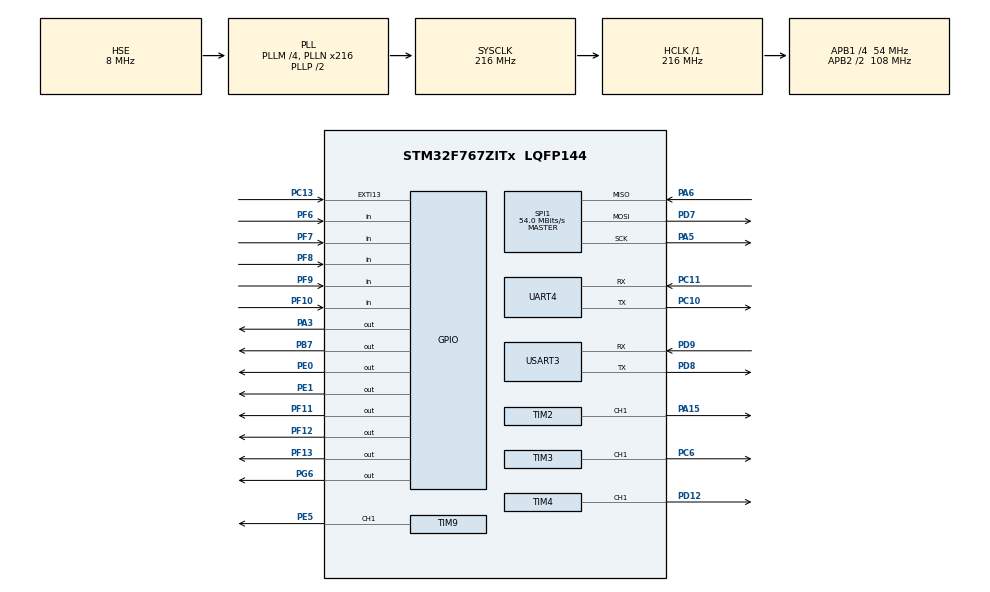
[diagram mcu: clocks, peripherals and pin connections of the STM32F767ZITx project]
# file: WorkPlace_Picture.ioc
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Mcu.Family=STM32F7
Mcu.Name=STM32F767ZITx
Mcu.Package=LQFP144
NVIC.PriorityGroup=NVIC_PRIORITYGROUP_2
NVIC.TIM2_IRQn=true\:0\:0\:false\:false\:true\:true\:true
NVIC.TIM3_IRQn=true\:0\:0\:false\:false\:true\:true\:true
NVIC.TIM4_IRQn=true\:0\:0\:false\:false\:true\:true\:true
NVIC.UART4_IRQn=true\:0\:0\:false\:false\:true\:true\:true
NVIC.USART3_IRQn=true\:0\:0\:false\:false\:true\:true\:true
PA0/WKUP.Mode=SYS_WakeUp0
PA0/WKUP.Signal=SYS_WKUP1
PA1.GPIO_Mode=GPIO_MODE_AF_PP
PA1.GPIO_PuPd=GPIO_NOPULL
PA1.GPIO_Speed=GPIO_SPEED_FREQ_VERY_HIGH
PA1.Signal=ETH_REF_CLK
PA10.GPIO_Mode=GPIO_MODE_AF_PP
PA10.GPIO_PuPd=GPIO_NOPULL
PA10.GPIO_Speed=GPIO_SPEED_FREQ_VERY_HIGH
PA10.Signal=USB_OTG_FS_ID
PA11.GPIO_Mode=GPIO_MODE_AF_PP
PA11.GPIO_PuPd=GPIO_NOPULL
PA11.GPIO_Speed=GPIO_SPEED_FREQ_VERY_HIGH
PA11.Signal=USB_OTG_FS_DM
PA12.GPIO_Mode=GPIO_MODE_AF_PP
PA12.GPIO_PuPd=GPIO_NOPULL
PA12.GPIO_Speed=GPIO_SPEED_FREQ_VERY_HIGH
PA12.Signal=USB_OTG_FS_DP
PA13.Mode=Serial_Wire
PA13.Signal=SYS_JTMS-SWDIO
PA14.Mode=Serial_Wire
PA14.Signal=SYS_JTCK-SWCLK
PA15.Signal=S_TIM2_CH1_ETR
PA2.GPIO_Mode=GPIO_MODE_AF_PP
PA2.GPIO_PuPd=GPIO_NOPULL
PA2.GPIO_Speed=GPIO_SPEED_FREQ_VERY_HIGH
PA2.Signal=ETH_MDIO
PA3.Signal=GPIO_Output
PA5.Mode=Full_Duplex_Master
PA5.Signal=SPI1_SCK
PA6.Mode=Full_Duplex_Master
PA6.Signal=SPI1_MISO
PA7.GPIO_Mode=GPIO_MODE_AF_PP
PA7.GPIO_PuPd=GPIO_NOPULL
PA7.GPIO_Speed=GPIO_SPEED_FREQ_VERY_HIGH
PA7.Signal=ETH_CRS_DV
PA8.GPIO_Mode=GPIO_MODE_AF_PP
PA8.GPIO_PuPd=GPIO_NOPULL
PA8.GPIO_Speed=GPIO_SPEED_FREQ_VERY_HIGH
PA8.Signal=USB_OTG_FS_SOF
PA9.GPIO_Mode=GPIO_MODE_INPUT
PA9.GPIO_PuPd=GPIO_NOPULL
PA9.Signal=USB_OTG_FS_VBUS
PB13.GPIO_Mode=GPIO_MODE_AF_PP
PB13.GPIO_PuPd=GPIO_NOPULL
PB13.GPIO_Speed=GPIO_SPEED_FREQ_VERY_HIGH
PB13.Signal=ETH_TXD1
PB3.Signal=SYS_JTDO-SWO
PB7.Signal=GPIO_Output
PC1.GPIO_Mode=GPIO_MODE_AF_PP
PC1.GPIO_PuPd=GPIO_NOPULL
PC1.GPIO_Speed=GPIO_SPEED_FREQ_VERY_HIGH
PC1.Signal=ETH_MDC
PC10.Mode=Asynchronous
PC10.Signal=UART4_TX
PC11.Mode=Asynchronous
PC11.Signal=UART4_RX
PC13.GPIO_ModeDefaultEXTI=GPIO_MODE_IT_RISING
PC13.GPIO_PuPd=GPIO_NOPULL
PC13.Signal=GPXTI13
PC14/OSC32_IN.Mode=LSE-External-Oscillator
PC14/OSC32_IN.Signal=RCC_OSC32_IN
PC15/OSC32_OUT.Mode=LSE-External-Oscillator
PC15/OSC32_OUT.Signal=RCC_OSC32_OUT
PC4.GPIO_Mode=GPIO_MODE_AF_PP
PC4.GPIO_PuPd=GPIO_NOPULL
PC4.GPIO_Speed=GPIO_SPEED_FREQ_VERY_HIGH
PC4.Signal=ETH_RXD0
PC5.GPIO_Mode=GPIO_MODE_AF_PP
PC5.GPIO_PuPd=GPIO_NOPULL
PC5.GPIO_Speed=GPIO_SPEED_FREQ_VERY_HIGH
PC5.Signal=ETH_RXD1
PC6.Signal=S_TIM3_CH1
PD12.Signal=S_TIM4_CH1
PD7.Mode=Full_Duplex_Master
PD7.Signal=SPI1_MOSI
PD8.GPIO_ModeDefaultPP=GPIO_MODE_AF_PP
PD8.GPIO_PuPd=GPIO_NOPULL
PD8.GPIO_Speed=GPIO_SPEED_FREQ_VERY_HIGH
PD8.Mode=Asynchronous
PD8.Signal=USART3_TX
PD9.GPIO_ModeDefaultPP=GPIO_MODE_AF_PP
PD9.GPIO_PuPd=GPIO_NOPULL
PD9.GPIO_Speed=GPIO_SPEED_FREQ_VERY_HIGH
PD9.Mode=Asynchronous
PD9.Signal=USART3_RX
PE0.Signal=GPIO_Output
PE1.Signal=GPIO_Output
PE5.Signal=S_TIM9_CH1
PF10.Signal=GPIO_Input
PF11.Signal=GPIO_Output
PF12.Signal=GPIO_Output
PF13.Signal=GPIO_Output
PF6.Signal=GPIO_Input
PF7.Signal=GPIO_Input
PF8.Signal=GPIO_Input
PF9.Signal=GPIO_Input
PG11.GPIO_Mode=GPIO_MODE_AF_PP
PG11.GPIO_PuPd=GPIO_NOPULL
PG11.GPIO_Speed=GPIO_SPEED_FREQ_VERY_HIGH
PG11.Signal=ETH_TX_EN
PG13.GPIO_Mode=GPIO_MODE_AF_PP
PG13.GPIO_PuPd=GPIO_NOPULL
PG13.GPIO_Speed=GPIO_SPEED_FREQ_VERY_HIGH
PG13.Signal=ETH_TXD0
PG6.Signal=GPIO_Output
PH0/OSC_IN.Mode=HSE-External-Clock-Source
PH0/OSC_IN.Signal=RCC_OSC_IN
PH1/OSC_OUT.Mode=HSE-External-Clock-Source
PH1/OSC_OUT.Signal=RCC_OSC_OUT
ProjectManager.HeapSize=0x200
ProjectManager.StackSize=0x400
ProjectManager.TargetToolchain=MDK-ARM V5
RCC.48MHZClocksFreq_Value=24000000
RCC.AHBFreq_Value=216000000
RCC.APB1CLKDivider=RCC_HCLK_DIV4
RCC.APB1Freq_Value=54000000
RCC.APB1TimFreq_Value=108000000
RCC.APB2CLKDivider=RCC_HCLK_DIV2
RCC.APB2Freq_Value=108000000
RCC.APB2TimFreq_Value=216000000
RCC.CortexFreq_Value=216000000
RCC.HCLKFreq_Value=216000000
RCC.HSE_VALUE=8000000
RCC.HSI_VALUE=16000000
RCC.PLLM=4
RCC.PLLMUL=RCC_PLL_MUL9
RCC.PLLN=216
RCC.PLLQ=9
RCC.PLLSourceVirtual=RCC_PLLSOURCE_HSE
RCC.PRESCALERUSB=RCC_USBCLKSOURCE_PLL_DIV1_5
RCC.SYSCLKFreq_VALUE=216000000
RCC.SYSCLKSource=RCC_SYSCLKSOURCE_PLLCLK
RCC.SYSCLKSourceVirtual=RCC_SYSCLKSOURCE_PLLCLK
RCC.USBFreq_Value=48000000
RCC.VCOOutputFreq_Value=432000000
SH.S_TIM2_CH1_ETR.0=TIM2_CH1,PWM Generation1 CH1
SH.S_TIM3_CH1.0=TIM3_CH1,PWM Generation1 CH1
SH.S_TIM4_CH1.0=TIM4_CH1,PWM Generation1 CH1
SH.S_TIM9_CH1.0=TIM9_CH1,PWM Generation1 CH1
SPI1.CalculateBaudRate=54.0 MBits/s
SPI1.DataSize=SPI_DATASIZE_8BIT
SPI1.Direction=SPI_DIRECTION_2LINES
SPI1.Mode=SPI_MODE_MASTER
SPI1.VirtualType=VM_MASTER
TIM14.Period=1
TIM14.Prescaler=108-1
TIM2.Channel-PWM\ Generation1\ CH1=TIM_CHANNEL_1
TIM2.Period=5000
TIM2.Prescaler=108-1
TIM2.Pulse-PWM\ Generation1\ CH1=100
TIM3.Channel-PWM\ Generation1\ CH1=TIM_CHANNEL_1
TIM3.Period=5000
TIM3.Prescaler=108-1
TIM3.Pulse-PWM\ Generation1\ CH1=100
TIM4.Channel-PWM\ Generation1\ CH1=TIM_CHANNEL_1
TIM4.Period=5000
TIM4.Prescaler=108-1
TIM4.Pulse-PWM\ Generation1\ CH1=100
TIM9.AutoReloadPreload=TIM_AUTORELOAD_PRELOAD_ENABLE
TIM9.Channel-PWM\ Generation1\ CH1=TIM_CHANNEL_1
TIM9.Period=20000
TIM9.Prescaler=216-1
TIM9.Pulse-PWM\ Generation1\ CH1=1350
USART3.VirtualMode-Asynchronous=VM_ASYNC
VP_TIM14_VS_ClockSourceINT.Mode=Enable_Timer
board=NUCLEO-F767ZI

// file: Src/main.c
/* USER CODE BEGIN Header */
/**
  ******************************************************************************
  * @file           : main.c
  * @brief          : Main program body
  ******************************************************************************
  * @attention
  *
  * <h2><center>&copy; Copyright (c) 2019 STMicroelectronics.
  * All rights reserved.</center></h2>
  *
  * This software component is licensed by ST under BSD 3-Clause license,
  * the "License"; You may not use this file except in compliance with the
  * License. You may obtain a copy of the License at:
  *                        opensource.org/licenses/BSD-3-Clause
  *
  ******************************************************************************
  */
/* USER CODE END Header */

#include "main.h"
#include "spi.h"
#include "tim.h"
#include "usart.h"
#include "gpio.h"

/* USER CODE BEGIN Includes */
#include "Delay.h"
#include "LCD_Driver.h"
#include "State_Show.h"
#include "GUI.h"
#include "Motor.h"
#include "cad.h"
#include "data_analysis.h"
#include "cut.h"
/* USER CODE END Includes */

void SystemClock_Config(void);

int main(void)
{

  /* MCU Configuration--------------------------------------------------------*/

  /* Reset of all peripherals, Initializes the Flash interface and the Systick. */
  HAL_Init();

  /* Configure the system clock */
  SystemClock_Config();

  /* Initialize all configured peripherals */
  MX_GPIO_Init();
  MX_TIM14_Init();
  MX_USART3_UART_Init();
  MX_SPI1_Init();
  MX_TIM4_Init();
  MX_UART4_Init();
  MX_TIM2_Init();
  MX_TIM3_Init();
  MX_TIM9_Init();
  /* USER CODE BEGIN 2 */
  //Motor_Init();
	//Cut_Init();
	Cut_Rec();
  /* USER CODE END 2 */

  /* Infinite loop */
  while (1)
  {

  }
}

void SystemClock_Config(void)
{
  RCC_OscInitTypeDef RCC_OscInitStruct = {0};
  RCC_ClkInitTypeDef RCC_ClkInitStruct = {0};
  RCC_PeriphCLKInitTypeDef PeriphClkInitStruct = {0};

  /** Configure LSE Drive Capability
  */
  HAL_PWR_EnableBkUpAccess();
  /** Configure the main internal regulator output voltage
  */
  __HAL_RCC_PWR_CLK_ENABLE();
  __HAL_PWR_VOLTAGESCALING_CONFIG(PWR_REGULATOR_VOLTAGE_SCALE1);
  /** Initializes the CPU, AHB and APB busses clocks
  */
  RCC_OscInitStruct.OscillatorType = RCC_OSCILLATORTYPE_HSE;
  RCC_OscInitStruct.HSEState = RCC_HSE_BYPASS;
  RCC_OscInitStruct.PLL.PLLState = RCC_PLL_ON;
  RCC_OscInitStruct.PLL.PLLSource = RCC_PLLSOURCE_HSE;
  RCC_OscInitStruct.PLL.PLLM = 4;
  RCC_OscInitStruct.PLL.PLLN = 216;
  RCC_OscInitStruct.PLL.PLLP = RCC_PLLP_DIV2;
  RCC_OscInitStruct.PLL.PLLQ = 9;
  if (HAL_RCC_OscConfig(&RCC_OscInitStruct) != HAL_OK)
  {
    Error_Handler();
  }
  /** Activate the Over-Drive mode
  */
  if (HAL_PWREx_EnableOverDrive() != HAL_OK)
  {
    Error_Handler();
  }
  /** Initializes the CPU, AHB and APB busses clocks
  */
  RCC_ClkInitStruct.ClockType = RCC_CLOCKTYPE_HCLK|RCC_CLOCKTYPE_SYSCLK
                              |RCC_CLOCKTYPE_PCLK1|RCC_CLOCKTYPE_PCLK2;
  RCC_ClkInitStruct.SYSCLKSource = RCC_SYSCLKSOURCE_PLLCLK;
  RCC_ClkInitStruct.AHBCLKDivider = RCC_SYSCLK_DIV1;
  RCC_ClkInitStruct.APB1CLKDivider = RCC_HCLK_DIV4;
  RCC_ClkInitStruct.APB2CLKDivider = RCC_HCLK_DIV2;

  if (HAL_RCC_ClockConfig(&RCC_ClkInitStruct, FLASH_LATENCY_7) != HAL_OK)
  {
    Error_Handler();
  }
  PeriphClkInitStruct.PeriphClockSelection = RCC_PERIPHCLK_USART3|RCC_PERIPHCLK_UART4;
  PeriphClkInitStruct.Usart3ClockSelection = RCC_USART3CLKSOURCE_PCLK1;
  PeriphClkInitStruct.Uart4ClockSelection = RCC_UART4CLKSOURCE_PCLK1;
  if (HAL_RCCEx_PeriphCLKConfig(&PeriphClkInitStruct) != HAL_OK)
  {
    Error_Handler();
  }
}

void Error_Handler(void)
{
}

/************************ (C) COPYRIGHT STMicroelectronics *****END OF FILE****/
